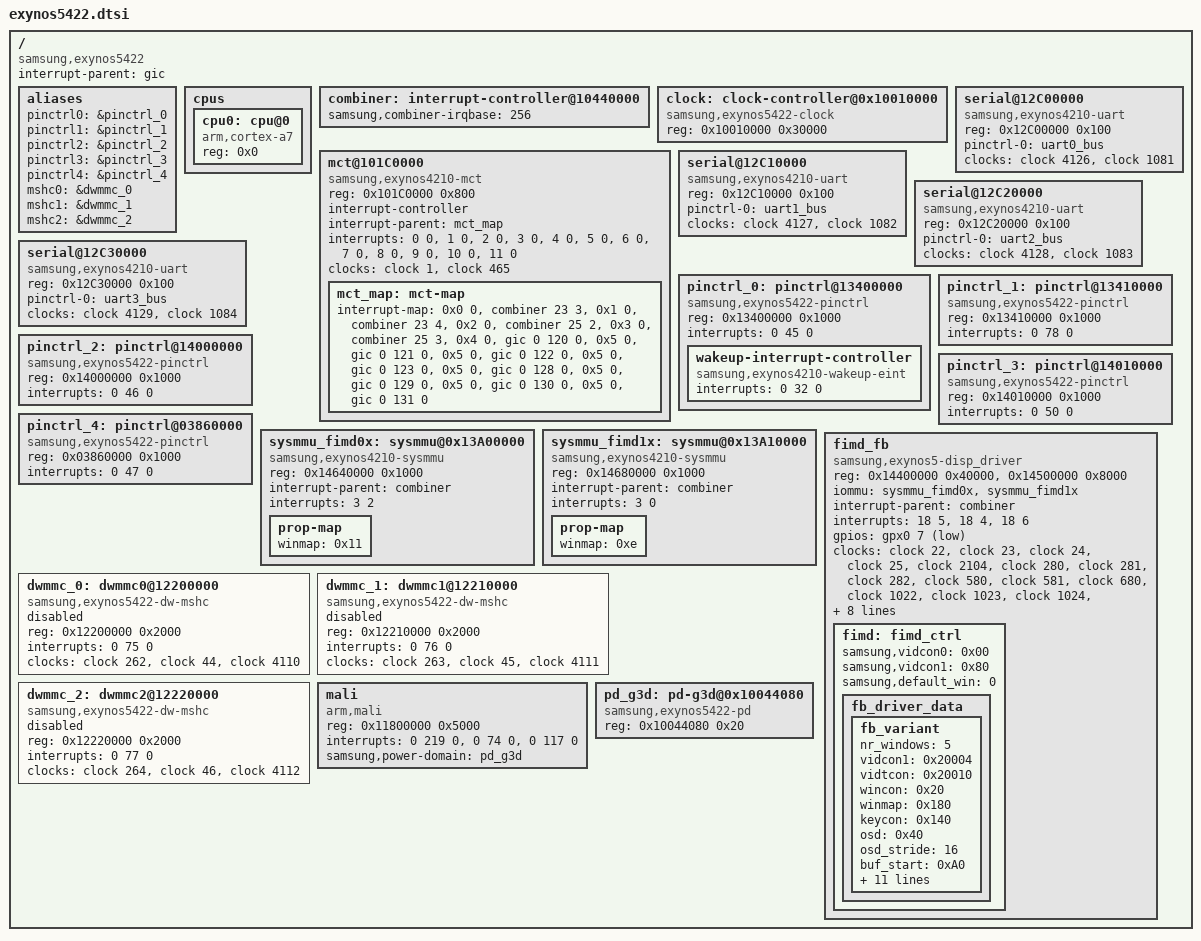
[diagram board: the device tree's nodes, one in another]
/*
 * SAMSUNG EXYNOS5422 SoC device tree source
 *
 * Copyright (c) 2013 Samsung Electronics Co., Ltd.
 *             http://www.samsung.com
 *
 * SAMSUNG EXYNOS5422 SoC device nodes are listed in this file.
 * EXYNOS5422 based board files can include this file and provide
 * values for board specfic bindings.
 *
 * This program is free software; you can redistribute it and/or modify
 * it under the terms of the GNU General Public License version 2 as
 * published by the Free Software Foundation.
 */

#include "exynos5.dtsi"
#include "exynos5422-pinctrl.dtsi"

/ {
	compatible = "samsung,exynos5422";
	interrupt-parent = <&gic>;

	aliases {
		pinctrl0 = &pinctrl_0;
		pinctrl1 = &pinctrl_1;
		pinctrl2 = &pinctrl_2;
		pinctrl3 = &pinctrl_3;
		pinctrl4 = &pinctrl_4;
		mshc0 = &dwmmc_0;
		mshc1 = &dwmmc_1;
		mshc2 = &dwmmc_2;
	};

	cpus {
		#address-cells = <1>;
		#size-cells = <0>;

		cpu0: cpu@0 {
			device_type = "cpu";
			compatible = "arm,cortex-a7";
			reg = <0x0>;
		};
	};

	combiner:interrupt-controller@10440000 {
		samsung,combiner-irqbase = <256>;
	};

	clock: clock-controller@0x10010000 {
		compatible = "samsung,exynos5422-clock";
		reg = <0x10010000 0x30000>;
		#clock-cells = <1>;
	};

	mct@101C0000 {
		compatible = "samsung,exynos4210-mct";
		reg = <0x101C0000 0x800>;
		interrupt-controller;
		#interrups-cells = <2>;
		interrupt-parent = <&mct_map>;
		interrupts = <0 0>, <1 0>, <2 0>, <3 0>,
			     <4 0>, <5 0>, <6 0>, <7 0>,
			     <8 0>, <9 0>, <10 0>, <11 0>;
		clocks = <&clock 1>, <&clock 465>;
		clock-names = "fin_pll", "mct";

		mct_map: mct-map {
			#interrupt-cells = <2>;
			#address-cells = <0>;
			#size-cells = <0>;
			interrupt-map = <0x0 0 &combiner 23 3>,
					<0x1 0 &combiner 23 4>,
					<0x2 0 &combiner 25 2>,
					<0x3 0 &combiner 25 3>,
					<0x4 0 &gic 0 120 0>,
					<0x5 0 &gic 0 121 0>,
					<0x5 0 &gic 0 122 0>,
					<0x5 0 &gic 0 123 0>,
					<0x5 0 &gic 0 128 0>,
					<0x5 0 &gic 0 129 0>,
					<0x5 0 &gic 0 130 0>,
					<0x5 0 &gic 0 131 0>;
		};
	};

	serial@12C00000 {
		compatible = "samsung,exynos4210-uart";
		reg = <0x12C00000 0x100>;
		pinctrl-names = "default";
		pinctrl-0 = <&uart0_bus>;
		clocks = <&clock 4126>, <&clock 1081>;
		clock-names = "sclk_uart0", "gate_uart0";
	};

	serial@12C10000 {
		compatible = "samsung,exynos4210-uart";
		reg = <0x12C10000 0x100>;
		pinctrl-names = "default";
		pinctrl-0 = <&uart1_bus>;
		clocks = <&clock 4127>, <&clock 1082>;
		clock-names = "sclk_uart1", "gate_uart1";
	};

	serial@12C20000 {
		compatible = "samsung,exynos4210-uart";
		reg = <0x12C20000 0x100>;
		pinctrl-names = "default";
		pinctrl-0 = <&uart2_bus>;
		clocks = <&clock 4128>, <&clock 1083>;
		clock-names = "sclk_uart2", "gate_uart2";
	};

	serial@12C30000 {
		compatible = "samsung,exynos4210-uart";
		reg = <0x12C30000 0x100>;
		pinctrl-names = "default";
		pinctrl-0 = <&uart3_bus>;
		clocks = <&clock 4129>, <&clock 1084>;
		clock-names = "sclk_uart3", "gate_uart3";
	};

	pinctrl_0: pinctrl@13400000 {
		compatible = "samsung,exynos5422-pinctrl";
		reg = <0x13400000 0x1000>;
		interrupts = <0 45 0>;

		wakeup-interrupt-controller {
			compatible = "samsung,exynos4210-wakeup-eint";
			interrupts = <0 32 0>;
		};
	};

	pinctrl_1: pinctrl@13410000 {
		compatible = "samsung,exynos5422-pinctrl";
		reg = <0x13410000 0x1000>;
		interrupts = <0 78 0>;
	};

	pinctrl_2: pinctrl@14000000 {
		compatible = "samsung,exynos5422-pinctrl";
		reg = <0x14000000 0x1000>;
		interrupts = <0 46 0>;
	};

	pinctrl_3: pinctrl@14010000 {
		compatible = "samsung,exynos5422-pinctrl";
		reg = <0x14010000 0x1000>;
		interrupts = <0 50 0>;
	};

	pinctrl_4: pinctrl@03860000 {
		compatible = "samsung,exynos5422-pinctrl";
		reg = <0x03860000 0x1000>;
		interrupts = <0 47 0>;
	};

	sysmmu_fimd0x: sysmmu@0x13A00000 {
		compatible = "samsung,exynos4210-sysmmu";
		reg = <0x14640000 0x1000>;
		interrupt-parent = <&combiner>;
		interrupts = <3 2>;
		prop-map {
			winmap = <0x11>;
		};
	};

	sysmmu_fimd1x: sysmmu@0x13A10000 {
		compatible = "samsung,exynos4210-sysmmu";
		reg = <0x14680000 0x1000>;
		interrupt-parent = <&combiner>;
		interrupts = <3 0>;
		prop-map {
			winmap = <0xe>;
		};
	};

	/* disp_driver */
	fimd_fb: fimd_fb {
		compatible = "samsung,exynos5-disp_driver";

		reg = <0x14400000 0x40000>, <0x14500000 0x8000>;

		iommu = <&sysmmu_fimd0x>, <&sysmmu_fimd1x>;

		/*samsung,power-domain = <&spd_decon>;*/

		/* interrupt num */
		interrupt-parent = <&combiner>;
		interrupts = <18 5>, <18 4>, <18 6>;
		interrupt-names = "vsync", "fifo", "lcd_sys";

		/*int-mipi-dsi0 = 113;
		int-mipi-dsi1 = 114;*/

		gpios = <&gpx0 7 0x3>;

		/* Clocks for the DECON driver */
		/* Clocks for the MIPI-DSI driver */
		clocks = <&clock 22>, <&clock 23>, <&clock 24>, <&clock 25>,
			<&clock 2104>, <&clock 280>, <&clock 281>, <&clock 282>,
			<&clock 580>, <&clock 581>, <&clock 680>,
			<&clock 1022>, <&clock 1023>, <&clock 1024>, <&clock 1025>,
			<&clock 1210>, <&clock 1214>, <&clock 1224>, <&clock 1233>,
			<&clock 2037>, <&clock 2053>, <&clock 2058>, <&clock 2067>,
			<&clock 2072>, <&clock 2077>, <&clock 2082>,
			<&clock 2100>, <&clock 2101>, <&clock 2102>,
			<&clock 2103>, /*<&clock 2104>,*/ <&clock 2105>,
			<&clock 4016>, <&clock 4021>,
			<&clock 4101>, <&clock 4102>, <&clock 4103>;
		clock-names = "sclk_pixel", "sclk_dp1_ext_mst_vid", "sclk_mipi1", "sclk_fimd1",
			"mout_fimd1", "aclk_200_disp1", "dsim1", "dp1",
			"aclk_300_disp1", "fimd1","aclk_400_disp1", "gate_pixel",
			"gate_dp1_ext_mst_vid", "gate_mipi1", "gate_fimd1",
			"gate_sclk_disp1", "gate_bus_disp1", "gate_top_sclk_disp1",
			"gate_ip_disp1", "mout_aclk_200_disp1_user", "mout_aclk_300_disp1",
			"mout_aclk_400_disp1", "mout_aclk_300_disp1_sw",
			"mout_aclk_400_disp1_sw", "mout_aclk_300_disp1_user",
			"mout_aclk_400_disp1_user", "mout_pixel", "mout_dp1_ext_mst_vid",
			"mout_mipi1", "mout_fimd1_opt", /*"mout_fimd1",*/ "mout_fimd1_final",
			"dout_aclk_300_disp1", "dout_aclk_400_disp1",
			"dout_dp1_ext_mst_vid", "dout_mipi1", "dout_fimd1";

		fimd: fimd_ctrl {
			samsung,vidcon0 = <0x00>;
			samsung,vidcon1 = <0x80>;
			samsung,default_win = <0>;
			fb_driver_data {
					fb_variant {
							nr_windows = <5>;
							vidcon1 = <0x20004>;
							vidtcon = <0x20010>;
							wincon = <0x20>;
							winmap = <0x180>;
							keycon = <0x140>;
							osd = <0x40>;
							osd_stride = <16>;
							buf_start = <0xA0>;
							buf_size  = <0x100>;
							buf_end   = <0xD0>;
							palette_0 = <0x2400>;
							palette_1 = <0x2800>;
							palette_2 = <0x2c00>;
							palette_3 = <0x3000>;
							palette_4 = <0x3400>;
							has_shadowcon = <1>;
							has_blendcon  = <1>;
							has_alphacon  = <1>;
							has_fixvclk   = <1>;
					};
				};
			};
		};

	dwmmc_0: dwmmc0@12200000 {
		compatible = "samsung,exynos5422-dw-mshc";
		reg = <0x12200000 0x2000>;
		interrupts = <0 75 0>;
		#address-cells = <1>;
		#size-cells = <0>;
		clocks = <&clock 262>, <&clock 44>, <&clock 4110>;
		clock-names = "biu", "gate_ciu", "dout_mmc_a";
		status = "disabled";
	};

	dwmmc_1: dwmmc1@12210000 {
		compatible = "samsung,exynos5422-dw-mshc";
		reg = <0x12210000 0x2000>;
		interrupts = <0 76 0>;
		#address-cells = <1>;
		#size-cells = <0>;
		clocks = <&clock 263>, <&clock 45>, <&clock 4111>;
		clock-names = "biu", "gate_ciu", "dout_mmc_a";
		status = "disabled";
	};

	dwmmc_2: dwmmc2@12220000 {
		compatible = "samsung,exynos5422-dw-mshc";
		reg = <0x12220000 0x2000>;
		interrupts = <0 77 0>;
		#address-cells = <1>;
		#size-cells = <0>;
		clocks = <&clock 264>, <&clock 46>, <&clock 4112>;
		clock-names = "biu", "gate_ciu", "dout_mmc_a";
		status = "disabled";
	};

	mali {
		compatible = "arm,mali";
		reg = <0x11800000 0x5000>;
		interrupts = <0 219 0>, <0 74 0>, <0 117 0>;
		samsung,power-domain = <&pd_g3d>;
	};

	pd_g3d: pd-g3d@0x10044080 {
        compatible = "samsung,exynos5422-pd";
        reg = <0x10044080 0x20>;
    };
};
